# CBASS0_FW register map
Vendor: Texas Instruments
Peripheral module from a debugger description file (folder am62A).
Registers are 32-bit, read-write, reset 0x0 unless marked. A register's access mark holds for its fields unless they carry their own. Offsets are as the file gives them; lines under a group give offsets from that group; [hi:lo] are bit positions; {n}, {i} and the like mark numbered series; 'fields as' and 'values as' point back to an identical list; <NAME> marks a mode.

## CBASS0_FW (part 1 of 2)
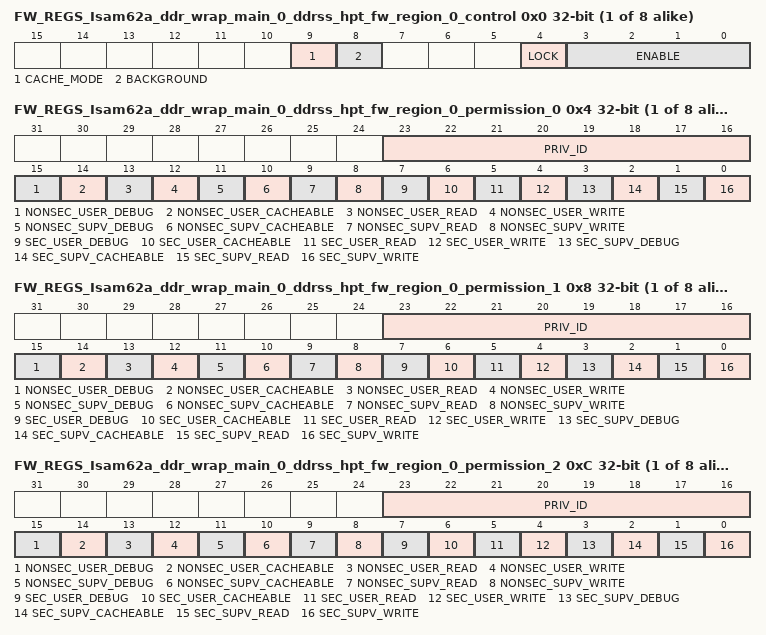
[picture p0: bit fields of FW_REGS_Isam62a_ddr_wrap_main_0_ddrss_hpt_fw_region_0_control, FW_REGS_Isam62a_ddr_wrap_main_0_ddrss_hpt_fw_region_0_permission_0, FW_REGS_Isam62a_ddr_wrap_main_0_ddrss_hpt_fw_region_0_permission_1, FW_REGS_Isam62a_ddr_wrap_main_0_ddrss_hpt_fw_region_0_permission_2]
{0x0+0x20*i} FW_REGS_Isam62a_ddr_wrap_main_0_ddrss_hpt_fw_region_{i}_control access not given (i=0..7) — The FW Region {i} Control Register defines the control fields for the slave Isam62a_ddr_wrap_main_0.ddrss_hpt region {i} firewall.
  [9] CACHE_MODE rw — Cache mode for region. Set to 1 to check cache permissions. Set to 0 to ignore cache permissions.
  [8] BACKGROUND rw — Background enable for region. There can be 1 backgroun region per FW and foreground regions can have overlapping addresses only with the background region.
  [4] LOCK — Lock region. Once set region values cannot be modified. (access R/W1TS)
  [3:0] ENABLE rw — Enable region. A value of 0xA enables, others disable.
{0x4+0x20*i} FW_REGS_Isam62a_ddr_wrap_main_0_ddrss_hpt_fw_region_{i}_permission_0 (i=0..7) — The FW Region {i} Permission 0 Register defines the permissions for the slave Isam62a_ddr_wrap_main_0.ddrss_hpt region {i} firewall.
  [23:16] PRIV_ID — Allowed privid.
  [15] NONSEC_USER_DEBUG — Non-secure user debug allowed.
  [14] NONSEC_USER_CACHEABLE — Non-secure user cacheable allowed.
  [13] NONSEC_USER_READ — Non-secure user read allowed.
  [12] NONSEC_USER_WRITE — Non-secure user write allowed.
  [11] NONSEC_SUPV_DEBUG — Non-secure supervisor debug allowed.
  [10] NONSEC_SUPV_CACHEABLE — Non-secure supervisor cacheable allowed.
  [9] NONSEC_SUPV_READ — Non-secure supervisor read allowed.
  [8] NONSEC_SUPV_WRITE — Non-secure supervisor write allowed.
  [7] SEC_USER_DEBUG — Secure user debug allowed.
  [6] SEC_USER_CACHEABLE — Secure user cacheable allowed.
  [5] SEC_USER_READ — Secure user read allowed.
  [4] SEC_USER_WRITE — Secure user write allowed.
  [3] SEC_SUPV_DEBUG — Secure supervisor debug allowed.
  [2] SEC_SUPV_CACHEABLE — Secure supervisor cacheable allowed.
  [1] SEC_SUPV_READ — Secure supervisor read allowed.
  [0] SEC_SUPV_WRITE — Secure supervisor write allowed.
{0x8+0x20*i} FW_REGS_Isam62a_ddr_wrap_main_0_ddrss_hpt_fw_region_{i}_permission_1 (i=0..7) — The FW Region {i} Permission 1 Register defines the permissions for the slave Isam62a_ddr_wrap_main_0.ddrss_hpt region {i} firewall.
  fields as FW_REGS_Isam62a_ddr_wrap_main_0_ddrss_hpt_fw_region_0_permission_0
{0xC+0x20*i} FW_REGS_Isam62a_ddr_wrap_main_0_ddrss_hpt_fw_region_{i}_permission_2 (i=0..7) — The FW Region {i} Permission 2 Register defines the permissions for the slave Isam62a_ddr_wrap_main_0.ddrss_hpt region {i} firewall.
  fields as FW_REGS_Isam62a_ddr_wrap_main_0_ddrss_hpt_fw_region_0_permission_0
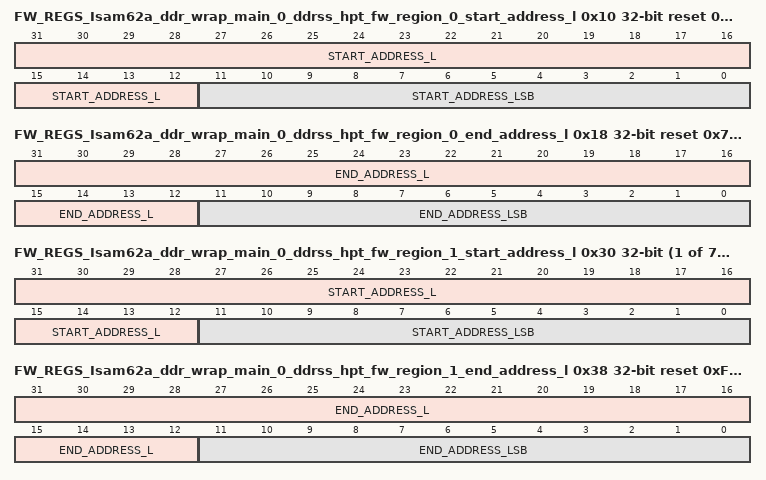
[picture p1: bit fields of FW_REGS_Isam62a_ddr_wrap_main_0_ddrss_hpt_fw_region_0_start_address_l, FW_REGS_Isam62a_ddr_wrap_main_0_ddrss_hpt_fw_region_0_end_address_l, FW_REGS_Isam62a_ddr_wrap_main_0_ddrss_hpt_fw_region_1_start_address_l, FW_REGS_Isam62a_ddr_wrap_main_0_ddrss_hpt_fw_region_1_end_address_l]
0x10 FW_REGS_Isam62a_ddr_wrap_main_0_ddrss_hpt_fw_region_0_start_address_l access per field reset 0x80000000 — The FW Region 0 Start Address Low Register defines the start address bits 31 to 0 for the slave Isam62a_ddr_wrap_main_0.ddrss_hpt region 0 firewall.
  [31:12] START_ADDRESS_L rw — Start address bits 31 to 12. Lowest 12 bits are forced to 0 as address must be 4KB aligned.
  [11:0] START_ADDRESS_LSB ro — Start address bits 11 to 0 are forced to 0 as address must be 4KB aligned.
{0x14+0x20*i} FW_REGS_Isam62a_ddr_wrap_main_0_ddrss_hpt_fw_region_{i}_start_address_h (i=0..7) — The FW Region {i} Start Address High Register defines the start address bits 47 to 32 for the slave Isam62a_ddr_wrap_main_0.ddrss_hpt region {i} firewall.
  [15:0] START_ADDRESS_H — Start address bits 47 to 32.
0x18 FW_REGS_Isam62a_ddr_wrap_main_0_ddrss_hpt_fw_region_0_end_address_l access per field reset 0x7FFFFFFF — The FW Region 0 End Address Low Register defines the end address bits 31 to 0 to include for the slave Isam62a_ddr_wrap_main_0.ddrss_hpt region 0 firewall.
  [31:12] END_ADDRESS_L rw — End address bits 31 to 12 to include in the match. Lowest 12 bits are forced to 1s as address must be 4KB aligned.
  [11:0] END_ADDRESS_LSB ro — End address bits 11 to 0 are forced to 1s as address must be 4KB aligned minus 1.
0x1C FW_REGS_Isam62a_ddr_wrap_main_0_ddrss_hpt_fw_region_0_end_address_h reset 0x8 — The FW Region 0 End Address High Register defines the end address bits 47 to 32 to include for the slave Isam62a_ddr_wrap_main_0.ddrss_hpt region 0 firewall.
  [15:0] END_ADDRESS_H — End address bits 47 to 32 to include in the match.
{0x10+0x20*i} FW_REGS_Isam62a_ddr_wrap_main_0_ddrss_hpt_fw_region_{i}_start_address_l access per field (i=1..7) — The FW Region {i} Start Address Low Register defines the start address bits 31 to 0 for the slave Isam62a_ddr_wrap_main_0.ddrss_hpt region {i} firewall.
  fields as FW_REGS_Isam62a_ddr_wrap_main_0_ddrss_hpt_fw_region_0_start_address_l
{0x18+0x20*i} FW_REGS_Isam62a_ddr_wrap_main_0_ddrss_hpt_fw_region_{i}_end_address_l access per field reset 0xFFF (i=1..7) — The FW Region {i} End Address Low Register defines the end address bits 31 to 0 to include for the slave Isam62a_ddr_wrap_main_0.ddrss_hpt region {i} firewall.
  fields as FW_REGS_Isam62a_ddr_wrap_main_0_ddrss_hpt_fw_region_0_end_address_l
{0x1C+0x20*i} FW_REGS_Isam62a_ddr_wrap_main_0_ddrss_hpt_fw_region_{i}_end_address_h (i=1..7) — The FW Region {i} End Address High Register defines the end address bits 47 to 32 to include for the slave Isam62a_ddr_wrap_main_0.ddrss_hpt region {i} firewall.
  fields as FW_REGS_Isam62a_ddr_wrap_main_0_ddrss_hpt_fw_region_0_end_address_h
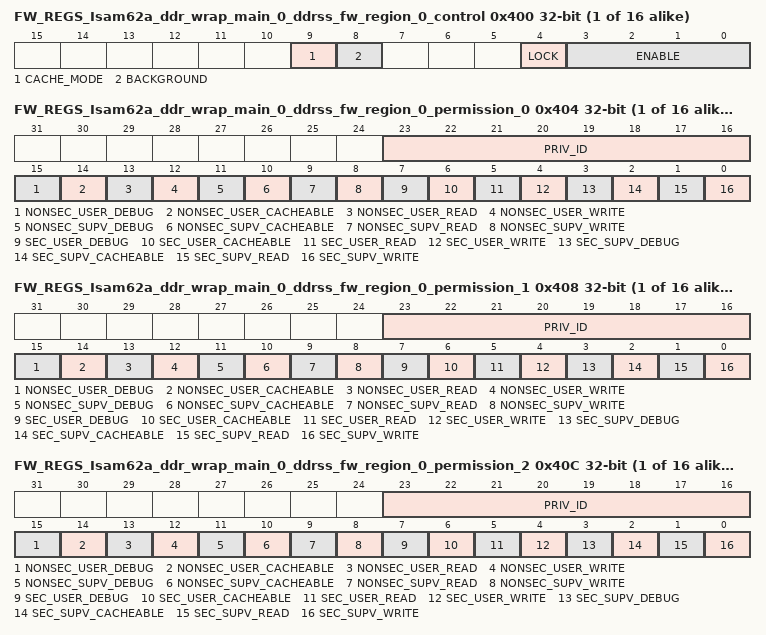
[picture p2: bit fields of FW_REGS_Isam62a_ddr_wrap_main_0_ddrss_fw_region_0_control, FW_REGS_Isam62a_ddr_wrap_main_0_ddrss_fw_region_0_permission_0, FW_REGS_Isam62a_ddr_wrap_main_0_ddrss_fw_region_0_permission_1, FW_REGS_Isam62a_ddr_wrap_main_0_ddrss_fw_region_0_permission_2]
{0x400+0x20*i} FW_REGS_Isam62a_ddr_wrap_main_0_ddrss_fw_region_{i}_control access not given (i=0..15) — The FW Region {i} Control Register defines the control fields for the slave Isam62a_ddr_wrap_main_0.ddrss region {i} firewall.
  fields as FW_REGS_Isam62a_ddr_wrap_main_0_ddrss_hpt_fw_region_0_control
{0x404+0x20*i} FW_REGS_Isam62a_ddr_wrap_main_0_ddrss_fw_region_{i}_permission_0 (i=0..15) — The FW Region {i} Permission 0 Register defines the permissions for the slave Isam62a_ddr_wrap_main_0.ddrss region {i} firewall.
  fields as FW_REGS_Isam62a_ddr_wrap_main_0_ddrss_hpt_fw_region_0_permission_0
{0x408+0x20*i} FW_REGS_Isam62a_ddr_wrap_main_0_ddrss_fw_region_{i}_permission_1 (i=0..15) — The FW Region {i} Permission 1 Register defines the permissions for the slave Isam62a_ddr_wrap_main_0.ddrss region {i} firewall.
  fields as FW_REGS_Isam62a_ddr_wrap_main_0_ddrss_hpt_fw_region_0_permission_0
{0x40C+0x20*i} FW_REGS_Isam62a_ddr_wrap_main_0_ddrss_fw_region_{i}_permission_2 (i=0..15) — The FW Region {i} Permission 2 Register defines the permissions for the slave Isam62a_ddr_wrap_main_0.ddrss region {i} firewall.
  fields as FW_REGS_Isam62a_ddr_wrap_main_0_ddrss_hpt_fw_region_0_permission_0
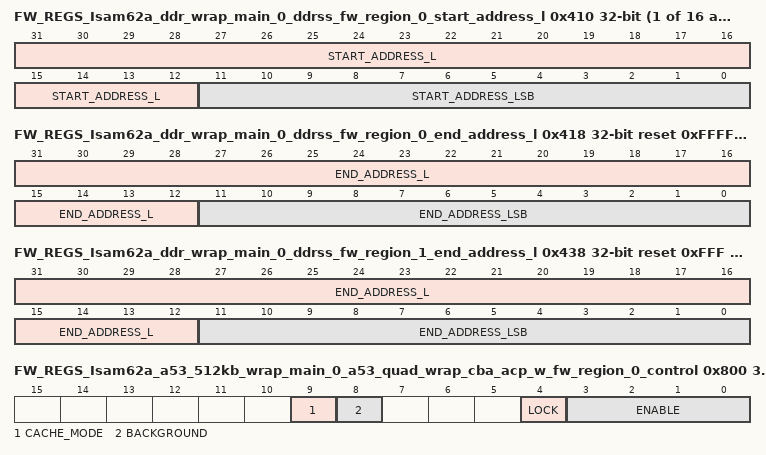
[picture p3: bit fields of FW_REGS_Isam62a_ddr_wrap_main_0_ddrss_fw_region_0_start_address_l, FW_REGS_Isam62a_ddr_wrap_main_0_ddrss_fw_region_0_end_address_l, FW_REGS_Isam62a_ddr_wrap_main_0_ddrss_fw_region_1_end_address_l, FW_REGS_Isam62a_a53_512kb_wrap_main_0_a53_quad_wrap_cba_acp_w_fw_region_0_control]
{0x410+0x20*i} FW_REGS_Isam62a_ddr_wrap_main_0_ddrss_fw_region_{i}_start_address_l access per field (i=0..15) — The FW Region {i} Start Address Low Register defines the start address bits 31 to 0 for the slave Isam62a_ddr_wrap_main_0.ddrss region {i} firewall.
  fields as FW_REGS_Isam62a_ddr_wrap_main_0_ddrss_hpt_fw_region_0_start_address_l
0x414 FW_REGS_Isam62a_ddr_wrap_main_0_ddrss_fw_region_0_start_address_h reset 0x9 — The FW Region 0 Start Address High Register defines the start address bits 47 to 32 for the slave Isam62a_ddr_wrap_main_0.ddrss region 0 firewall.
  [15:0] START_ADDRESS_H — Start address bits 47 to 32.
0x418 FW_REGS_Isam62a_ddr_wrap_main_0_ddrss_fw_region_0_end_address_l access per field reset 0xFFFFFFFF — The FW Region 0 End Address Low Register defines the end address bits 31 to 0 to include for the slave Isam62a_ddr_wrap_main_0.ddrss region 0 firewall.
  fields as FW_REGS_Isam62a_ddr_wrap_main_0_ddrss_hpt_fw_region_0_end_address_l
0x41C FW_REGS_Isam62a_ddr_wrap_main_0_ddrss_fw_region_0_end_address_h reset 0x10 — The FW Region 0 End Address High Register defines the end address bits 47 to 32 to include for the slave Isam62a_ddr_wrap_main_0.ddrss region 0 firewall.
  fields as FW_REGS_Isam62a_ddr_wrap_main_0_ddrss_hpt_fw_region_0_end_address_h
{0x414+0x20*i} FW_REGS_Isam62a_ddr_wrap_main_0_ddrss_fw_region_{i}_start_address_h (i=1..15) — The FW Region {i} Start Address High Register defines the start address bits 47 to 32 for the slave Isam62a_ddr_wrap_main_0.ddrss region {i} firewall.
  [15:0] START_ADDRESS_H — Start address bits 47 to 32.
{0x418+0x20*i} FW_REGS_Isam62a_ddr_wrap_main_0_ddrss_fw_region_{i}_end_address_l access per field reset 0xFFF (i=1..15) — The FW Region {i} End Address Low Register defines the end address bits 31 to 0 to include for the slave Isam62a_ddr_wrap_main_0.ddrss region {i} firewall.
  fields as FW_REGS_Isam62a_ddr_wrap_main_0_ddrss_hpt_fw_region_0_end_address_l
{0x41C+0x20*i} FW_REGS_Isam62a_ddr_wrap_main_0_ddrss_fw_region_{i}_end_address_h (i=1..15) — The FW Region {i} End Address High Register defines the end address bits 47 to 32 to include for the slave Isam62a_ddr_wrap_main_0.ddrss region {i} firewall.
  fields as FW_REGS_Isam62a_ddr_wrap_main_0_ddrss_hpt_fw_region_0_end_address_h
{0x800+0x20*i} FW_REGS_Isam62a_a53_512kb_wrap_main_0_a53_quad_wrap_cba_acp_w_fw_region_{i}_control access not given (i=0..7) — The FW Region {i} Control Register defines the control fields for the slave Isam62a_a53_512kb_wrap_main_0.a53_quad_wrap_cba_acp_w region {i} firewall.
  fields as FW_REGS_Isam62a_ddr_wrap_main_0_ddrss_hpt_fw_region_0_control
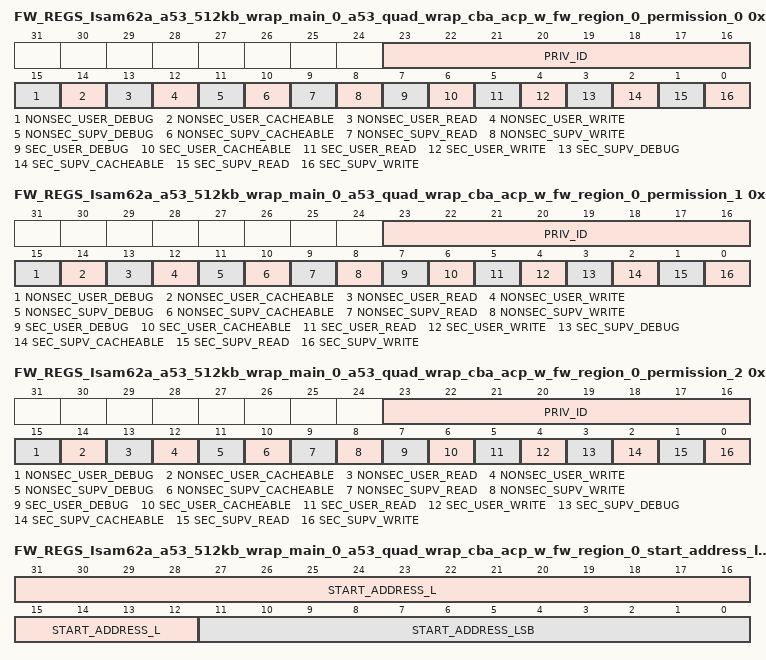
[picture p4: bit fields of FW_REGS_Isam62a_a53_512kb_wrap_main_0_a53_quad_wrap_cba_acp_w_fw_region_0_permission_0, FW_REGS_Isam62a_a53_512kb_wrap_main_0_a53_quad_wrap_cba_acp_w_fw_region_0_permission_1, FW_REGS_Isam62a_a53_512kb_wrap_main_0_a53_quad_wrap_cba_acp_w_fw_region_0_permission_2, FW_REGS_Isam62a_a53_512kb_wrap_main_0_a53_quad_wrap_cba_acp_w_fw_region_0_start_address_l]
{0x804+0x20*i} FW_REGS_Isam62a_a53_512kb_wrap_main_0_a53_quad_wrap_cba_acp_w_fw_region_{i}_permission_0 (i=0..7) — The FW Region {i} Permission 0 Register defines the permissions for the slave Isam62a_a53_512kb_wrap_main_0.a53_quad_wrap_cba_acp_w region {i} firewall.
  fields as FW_REGS_Isam62a_ddr_wrap_main_0_ddrss_hpt_fw_region_0_permission_0
{0x808+0x20*i} FW_REGS_Isam62a_a53_512kb_wrap_main_0_a53_quad_wrap_cba_acp_w_fw_region_{i}_permission_1 (i=0..7) — The FW Region {i} Permission 1 Register defines the permissions for the slave Isam62a_a53_512kb_wrap_main_0.a53_quad_wrap_cba_acp_w region {i} firewall.
  fields as FW_REGS_Isam62a_ddr_wrap_main_0_ddrss_hpt_fw_region_0_permission_0
{0x80C+0x20*i} FW_REGS_Isam62a_a53_512kb_wrap_main_0_a53_quad_wrap_cba_acp_w_fw_region_{i}_permission_2 (i=0..7) — The FW Region {i} Permission 2 Register defines the permissions for the slave Isam62a_a53_512kb_wrap_main_0.a53_quad_wrap_cba_acp_w region {i} firewall.
  fields as FW_REGS_Isam62a_ddr_wrap_main_0_ddrss_hpt_fw_region_0_permission_0
{0x810+0x20*i} FW_REGS_Isam62a_a53_512kb_wrap_main_0_a53_quad_wrap_cba_acp_w_fw_region_{i}_start_address_l access per field (i=0..7) — The FW Region {i} Start Address Low Register defines the start address bits 31 to 0 for the slave Isam62a_a53_512kb_wrap_main_0.a53_quad_wrap_cba_acp_w region {i} firewall.
  fields as FW_REGS_Isam62a_ddr_wrap_main_0_ddrss_hpt_fw_region_0_start_address_l
{0x814+0x20*i} FW_REGS_Isam62a_a53_512kb_wrap_main_0_a53_quad_wrap_cba_acp_w_fw_region_{i}_start_address_h (i=0..7) — The FW Region {i} Start Address High Register defines the start address bits 47 to 32 for the slave Isam62a_a53_512kb_wrap_main_0.a53_quad_wrap_cba_acp_w region {i} firewall.
  [15:0] START_ADDRESS_H — Start address bits 47 to 32.
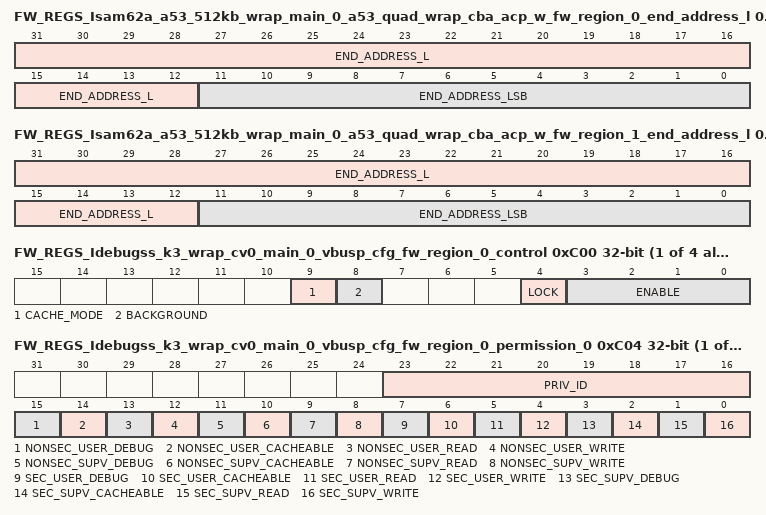
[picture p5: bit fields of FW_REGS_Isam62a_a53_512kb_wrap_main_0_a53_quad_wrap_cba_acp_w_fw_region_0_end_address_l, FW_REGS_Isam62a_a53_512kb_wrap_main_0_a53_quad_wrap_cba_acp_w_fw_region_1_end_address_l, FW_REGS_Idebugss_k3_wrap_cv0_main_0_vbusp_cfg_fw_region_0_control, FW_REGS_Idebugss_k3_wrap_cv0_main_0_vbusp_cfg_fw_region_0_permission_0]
0x818 FW_REGS_Isam62a_a53_512kb_wrap_main_0_a53_quad_wrap_cba_acp_w_fw_region_0_end_address_l access per field reset 0xFFFFFFFF — The FW Region 0 End Address Low Register defines the end address bits 31 to 0 to include for the slave Isam62a_a53_512kb_wrap_main_0.a53_quad_wrap_cba_acp_w region 0 firewall.
  fields as FW_REGS_Isam62a_ddr_wrap_main_0_ddrss_hpt_fw_region_0_end_address_l
0x81C FW_REGS_Isam62a_a53_512kb_wrap_main_0_a53_quad_wrap_cba_acp_w_fw_region_0_end_address_h reset 0xF — The FW Region 0 End Address High Register defines the end address bits 47 to 32 to include for the slave Isam62a_a53_512kb_wrap_main_0.a53_quad_wrap_cba_acp_w region 0 firewall.
  fields as FW_REGS_Isam62a_ddr_wrap_main_0_ddrss_hpt_fw_region_0_end_address_h
{0x818+0x20*i} FW_REGS_Isam62a_a53_512kb_wrap_main_0_a53_quad_wrap_cba_acp_w_fw_region_{i}_end_address_l access per field reset 0xFFF (i=1..7) — The FW Region {i} End Address Low Register defines the end address bits 31 to 0 to include for the slave Isam62a_a53_512kb_wrap_main_0.a53_quad_wrap_cba_acp_w region {i} firewall.
  fields as FW_REGS_Isam62a_ddr_wrap_main_0_ddrss_hpt_fw_region_0_end_address_l
{0x81C+0x20*i} FW_REGS_Isam62a_a53_512kb_wrap_main_0_a53_quad_wrap_cba_acp_w_fw_region_{i}_end_address_h (i=1..7) — The FW Region {i} End Address High Register defines the end address bits 47 to 32 to include for the slave Isam62a_a53_512kb_wrap_main_0.a53_quad_wrap_cba_acp_w region {i} firewall.
  fields as FW_REGS_Isam62a_ddr_wrap_main_0_ddrss_hpt_fw_region_0_end_address_h
{0xC00+0x20*i} FW_REGS_Idebugss_k3_wrap_cv0_main_0_vbusp_cfg_fw_region_{i}_control access not given (i=0..3) — The FW Region {i} Control Register defines the control fields for the slave Idebugss_k3_wrap_cv0_main_0.vbusp_cfg region {i} firewall.
  fields as FW_REGS_Isam62a_ddr_wrap_main_0_ddrss_hpt_fw_region_0_control
{0xC04+0x20*i} FW_REGS_Idebugss_k3_wrap_cv0_main_0_vbusp_cfg_fw_region_{i}_permission_0 (i=0..3) — The FW Region {i} Permission 0 Register defines the permissions for the slave Idebugss_k3_wrap_cv0_main_0.vbusp_cfg region {i} firewall.
  fields as FW_REGS_Isam62a_ddr_wrap_main_0_ddrss_hpt_fw_region_0_permission_0
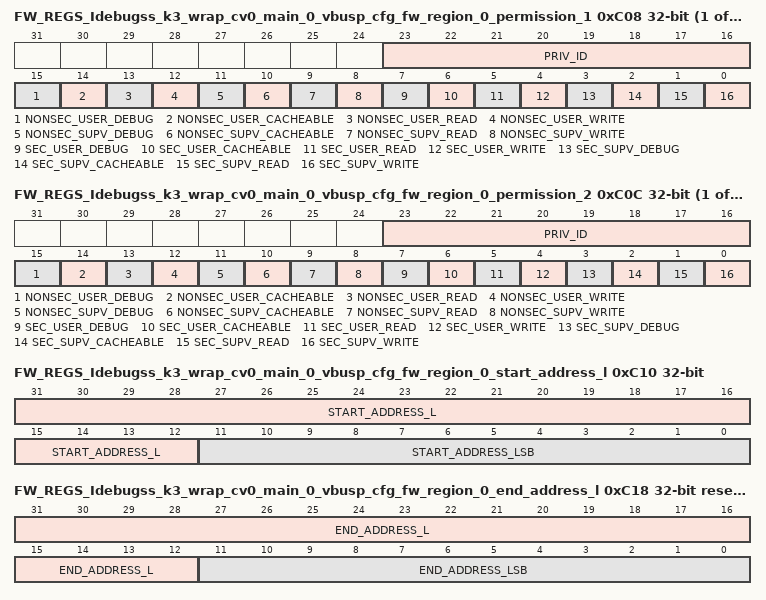
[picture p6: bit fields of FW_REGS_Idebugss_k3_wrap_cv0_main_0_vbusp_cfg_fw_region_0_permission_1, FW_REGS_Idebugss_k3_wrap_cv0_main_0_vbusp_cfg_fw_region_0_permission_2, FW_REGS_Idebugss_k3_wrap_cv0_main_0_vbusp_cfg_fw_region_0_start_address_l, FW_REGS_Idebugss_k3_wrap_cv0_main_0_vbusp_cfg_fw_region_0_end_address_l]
{0xC08+0x20*i} FW_REGS_Idebugss_k3_wrap_cv0_main_0_vbusp_cfg_fw_region_{i}_permission_1 (i=0..3) — The FW Region {i} Permission 1 Register defines the permissions for the slave Idebugss_k3_wrap_cv0_main_0.vbusp_cfg region {i} firewall.
  fields as FW_REGS_Isam62a_ddr_wrap_main_0_ddrss_hpt_fw_region_0_permission_0
{0xC0C+0x20*i} FW_REGS_Idebugss_k3_wrap_cv0_main_0_vbusp_cfg_fw_region_{i}_permission_2 (i=0..3) — The FW Region {i} Permission 2 Register defines the permissions for the slave Idebugss_k3_wrap_cv0_main_0.vbusp_cfg region {i} firewall.
  fields as FW_REGS_Isam62a_ddr_wrap_main_0_ddrss_hpt_fw_region_0_permission_0
0xC10 FW_REGS_Idebugss_k3_wrap_cv0_main_0_vbusp_cfg_fw_region_0_start_address_l access per field — The FW Region 0 Start Address Low Register defines the start address bits 31 to 0 for the slave Idebugss_k3_wrap_cv0_main_0.vbusp_cfg region 0 firewall.
  fields as FW_REGS_Isam62a_ddr_wrap_main_0_ddrss_hpt_fw_region_0_start_address_l
{0xC14+0x20*i} FW_REGS_Idebugss_k3_wrap_cv0_main_0_vbusp_cfg_fw_region_{i}_start_address_h reset 0x7 (i=0..3) — The FW Region {i} Start Address High Register defines the start address bits 47 to 32 for the slave Idebugss_k3_wrap_cv0_main_0.vbusp_cfg region {i} firewall.
  [15:0] START_ADDRESS_H — Start address bits 47 to 32.
0xC18 FW_REGS_Idebugss_k3_wrap_cv0_main_0_vbusp_cfg_fw_region_0_end_address_l access per field reset 0xFFF — The FW Region 0 End Address Low Register defines the end address bits 31 to 0 to include for the slave Idebugss_k3_wrap_cv0_main_0.vbusp_cfg region 0 firewall.
  fields as FW_REGS_Isam62a_ddr_wrap_main_0_ddrss_hpt_fw_region_0_end_address_l
{0xC1C+0x20*i} FW_REGS_Idebugss_k3_wrap_cv0_main_0_vbusp_cfg_fw_region_{i}_end_address_h reset 0x7 (i=0..3) — The FW Region {i} End Address High Register defines the end address bits 47 to 32 to include for the slave Idebugss_k3_wrap_cv0_main_0.vbusp_cfg region {i} firewall.
  fields as FW_REGS_Isam62a_ddr_wrap_main_0_ddrss_hpt_fw_region_0_end_address_h
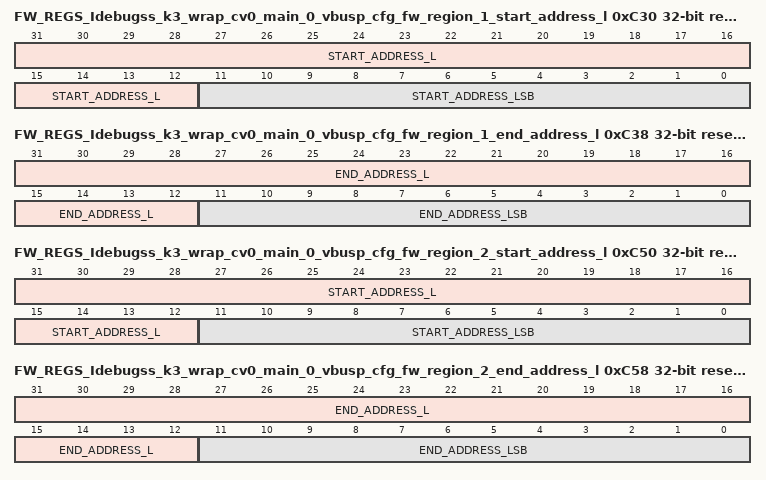
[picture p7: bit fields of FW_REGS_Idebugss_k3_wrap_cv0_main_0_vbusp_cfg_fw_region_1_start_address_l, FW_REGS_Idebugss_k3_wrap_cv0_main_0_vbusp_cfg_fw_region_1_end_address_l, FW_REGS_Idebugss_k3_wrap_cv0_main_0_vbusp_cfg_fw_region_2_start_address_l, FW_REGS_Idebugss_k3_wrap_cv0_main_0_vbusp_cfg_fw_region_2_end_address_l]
0xC30 FW_REGS_Idebugss_k3_wrap_cv0_main_0_vbusp_cfg_fw_region_1_start_address_l access per field reset 0x1000 — The FW Region 1 Start Address Low Register defines the start address bits 31 to 0 for the slave Idebugss_k3_wrap_cv0_main_0.vbusp_cfg region 1 firewall.
  fields as FW_REGS_Isam62a_ddr_wrap_main_0_ddrss_hpt_fw_region_0_start_address_l
0xC38 FW_REGS_Idebugss_k3_wrap_cv0_main_0_vbusp_cfg_fw_region_1_end_address_l access per field reset 0x1FFF — The FW Region 1 End Address Low Register defines the end address bits 31 to 0 to include for the slave Idebugss_k3_wrap_cv0_main_0.vbusp_cfg region 1 firewall.
  fields as FW_REGS_Isam62a_ddr_wrap_main_0_ddrss_hpt_fw_region_0_end_address_l
0xC50 FW_REGS_Idebugss_k3_wrap_cv0_main_0_vbusp_cfg_fw_region_2_start_address_l access per field reset 0x2000 — The FW Region 2 Start Address Low Register defines the start address bits 31 to 0 for the slave Idebugss_k3_wrap_cv0_main_0.vbusp_cfg region 2 firewall.
  fields as FW_REGS_Isam62a_ddr_wrap_main_0_ddrss_hpt_fw_region_0_start_address_l
0xC58 FW_REGS_Idebugss_k3_wrap_cv0_main_0_vbusp_cfg_fw_region_2_end_address_l access per field reset 0x2FFF — The FW Region 2 End Address Low Register defines the end address bits 31 to 0 to include for the slave Idebugss_k3_wrap_cv0_main_0.vbusp_cfg region 2 firewall.
  fields as FW_REGS_Isam62a_ddr_wrap_main_0_ddrss_hpt_fw_region_0_end_address_l
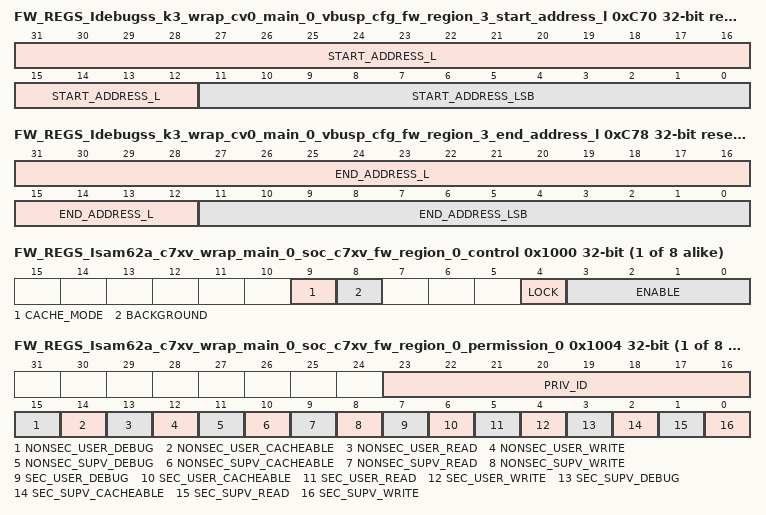
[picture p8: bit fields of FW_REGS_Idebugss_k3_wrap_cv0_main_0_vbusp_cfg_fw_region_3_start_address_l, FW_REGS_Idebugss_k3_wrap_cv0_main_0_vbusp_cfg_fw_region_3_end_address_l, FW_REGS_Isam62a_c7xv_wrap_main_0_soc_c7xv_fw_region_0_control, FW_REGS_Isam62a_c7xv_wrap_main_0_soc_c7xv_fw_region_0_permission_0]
0xC70 FW_REGS_Idebugss_k3_wrap_cv0_main_0_vbusp_cfg_fw_region_3_start_address_l access per field reset 0x2000 — The FW Region 3 Start Address Low Register defines the start address bits 31 to 0 for the slave Idebugss_k3_wrap_cv0_main_0.vbusp_cfg region 3 firewall.
  fields as FW_REGS_Isam62a_ddr_wrap_main_0_ddrss_hpt_fw_region_0_start_address_l
0xC78 FW_REGS_Idebugss_k3_wrap_cv0_main_0_vbusp_cfg_fw_region_3_end_address_l access per field reset 0x2FFF — The FW Region 3 End Address Low Register defines the end address bits 31 to 0 to include for the slave Idebugss_k3_wrap_cv0_main_0.vbusp_cfg region 3 firewall.
  fields as FW_REGS_Isam62a_ddr_wrap_main_0_ddrss_hpt_fw_region_0_end_address_l
{0x1000+0x20*i} FW_REGS_Isam62a_c7xv_wrap_main_0_soc_c7xv_fw_region_{i}_control access not given (i=0..7) — The FW Region {i} Control Register defines the control fields for the slave Isam62a_c7xv_wrap_main_0.soc_c7xv region {i} firewall.
  fields as FW_REGS_Isam62a_ddr_wrap_main_0_ddrss_hpt_fw_region_0_control
{0x1004+0x20*i} FW_REGS_Isam62a_c7xv_wrap_main_0_soc_c7xv_fw_region_{i}_permission_0 (i=0..7) — The FW Region {i} Permission 0 Register defines the permissions for the slave Isam62a_c7xv_wrap_main_0.soc_c7xv region {i} firewall.
  fields as FW_REGS_Isam62a_ddr_wrap_main_0_ddrss_hpt_fw_region_0_permission_0
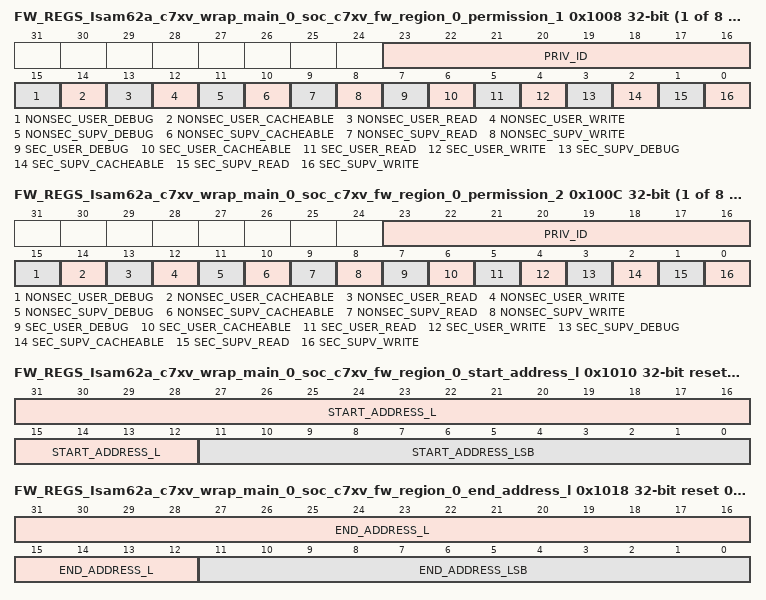
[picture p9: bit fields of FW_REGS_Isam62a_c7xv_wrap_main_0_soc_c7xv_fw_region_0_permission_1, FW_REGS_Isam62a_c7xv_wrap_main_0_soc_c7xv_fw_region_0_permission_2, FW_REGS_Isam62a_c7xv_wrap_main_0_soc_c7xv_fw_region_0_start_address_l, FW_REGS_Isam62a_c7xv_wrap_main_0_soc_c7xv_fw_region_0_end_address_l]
{0x1008+0x20*i} FW_REGS_Isam62a_c7xv_wrap_main_0_soc_c7xv_fw_region_{i}_permission_1 (i=0..7) — The FW Region {i} Permission 1 Register defines the permissions for the slave Isam62a_c7xv_wrap_main_0.soc_c7xv region {i} firewall.
  fields as FW_REGS_Isam62a_ddr_wrap_main_0_ddrss_hpt_fw_region_0_permission_0
{0x100C+0x20*i} FW_REGS_Isam62a_c7xv_wrap_main_0_soc_c7xv_fw_region_{i}_permission_2 (i=0..7) — The FW Region {i} Permission 2 Register defines the permissions for the slave Isam62a_c7xv_wrap_main_0.soc_c7xv region {i} firewall.
  fields as FW_REGS_Isam62a_ddr_wrap_main_0_ddrss_hpt_fw_region_0_permission_0
0x1010 FW_REGS_Isam62a_c7xv_wrap_main_0_soc_c7xv_fw_region_0_start_address_l access per field reset 0x7E000000 — The FW Region 0 Start Address Low Register defines the start address bits 31 to 0 for the slave Isam62a_c7xv_wrap_main_0.soc_c7xv region 0 firewall.
  fields as FW_REGS_Isam62a_ddr_wrap_main_0_ddrss_hpt_fw_region_0_start_address_l
{0x1014+0x20*i} FW_REGS_Isam62a_c7xv_wrap_main_0_soc_c7xv_fw_region_{i}_start_address_h (i=0..7) — The FW Region {i} Start Address High Register defines the start address bits 47 to 32 for the slave Isam62a_c7xv_wrap_main_0.soc_c7xv region {i} firewall.
  [15:0] START_ADDRESS_H — Start address bits 47 to 32.
0x1018 FW_REGS_Isam62a_c7xv_wrap_main_0_soc_c7xv_fw_region_0_end_address_l access per field reset 0x7E0FFFFF — The FW Region 0 End Address Low Register defines the end address bits 31 to 0 to include for the slave Isam62a_c7xv_wrap_main_0.soc_c7xv region 0 firewall.
  fields as FW_REGS_Isam62a_ddr_wrap_main_0_ddrss_hpt_fw_region_0_end_address_l
{0x101C+0x20*i} FW_REGS_Isam62a_c7xv_wrap_main_0_soc_c7xv_fw_region_{i}_end_address_h (i=0..7) — The FW Region {i} End Address High Register defines the end address bits 47 to 32 to include for the slave Isam62a_c7xv_wrap_main_0.soc_c7xv region {i} firewall.
  fields as FW_REGS_Isam62a_ddr_wrap_main_0_ddrss_hpt_fw_region_0_end_address_h
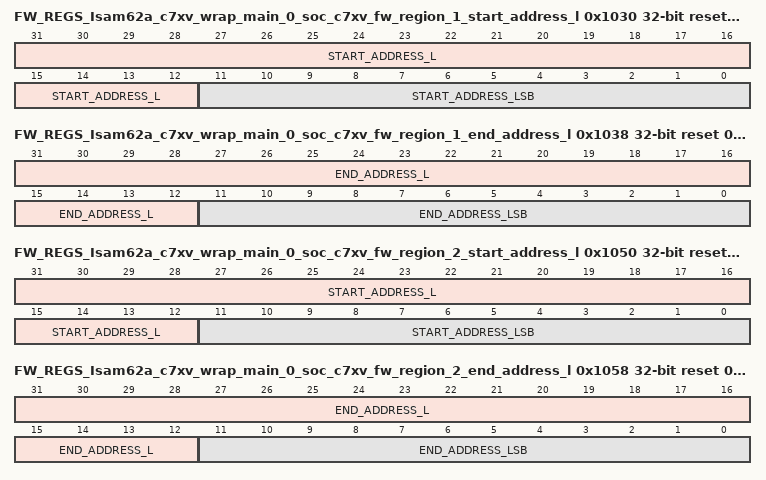
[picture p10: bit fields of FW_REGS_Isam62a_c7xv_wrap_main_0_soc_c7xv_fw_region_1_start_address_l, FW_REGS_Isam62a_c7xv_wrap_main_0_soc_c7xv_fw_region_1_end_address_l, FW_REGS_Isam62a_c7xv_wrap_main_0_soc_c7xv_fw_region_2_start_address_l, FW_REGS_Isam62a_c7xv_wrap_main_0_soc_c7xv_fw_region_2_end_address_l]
0x1030 FW_REGS_Isam62a_c7xv_wrap_main_0_soc_c7xv_fw_region_1_start_address_l access per field reset 0x7F000000 — The FW Region 1 Start Address Low Register defines the start address bits 31 to 0 for the slave Isam62a_c7xv_wrap_main_0.soc_c7xv region 1 firewall.
  fields as FW_REGS_Isam62a_ddr_wrap_main_0_ddrss_hpt_fw_region_0_start_address_l
0x1038 FW_REGS_Isam62a_c7xv_wrap_main_0_soc_c7xv_fw_region_1_end_address_l access per field reset 0x7F03FFFF — The FW Region 1 End Address Low Register defines the end address bits 31 to 0 to include for the slave Isam62a_c7xv_wrap_main_0.soc_c7xv region 1 firewall.
  fields as FW_REGS_Isam62a_ddr_wrap_main_0_ddrss_hpt_fw_region_0_end_address_l
0x1050 FW_REGS_Isam62a_c7xv_wrap_main_0_soc_c7xv_fw_region_2_start_address_l access per field reset 0x7C000000 — The FW Region 2 Start Address Low Register defines the start address bits 31 to 0 for the slave Isam62a_c7xv_wrap_main_0.soc_c7xv region 2 firewall.
  fields as FW_REGS_Isam62a_ddr_wrap_main_0_ddrss_hpt_fw_region_0_start_address_l
0x1058 FW_REGS_Isam62a_c7xv_wrap_main_0_soc_c7xv_fw_region_2_end_address_l access per field reset 0x7C01FFFF — The FW Region 2 End Address Low Register defines the end address bits 31 to 0 to include for the slave Isam62a_c7xv_wrap_main_0.soc_c7xv region 2 firewall.
  fields as FW_REGS_Isam62a_ddr_wrap_main_0_ddrss_hpt_fw_region_0_end_address_l
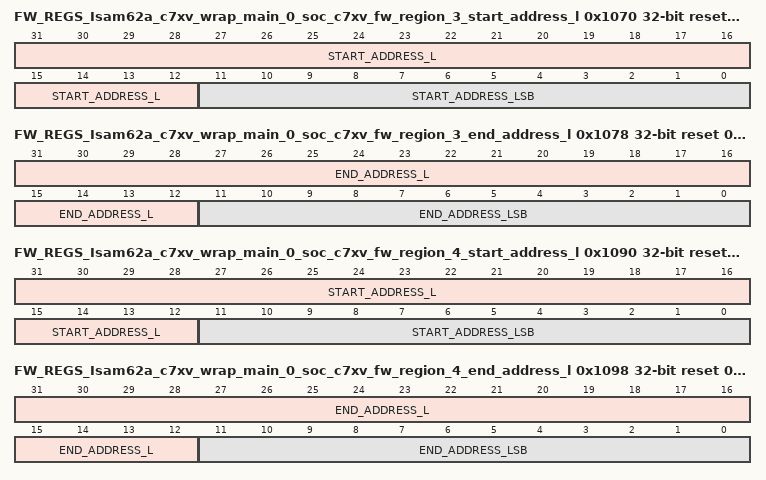
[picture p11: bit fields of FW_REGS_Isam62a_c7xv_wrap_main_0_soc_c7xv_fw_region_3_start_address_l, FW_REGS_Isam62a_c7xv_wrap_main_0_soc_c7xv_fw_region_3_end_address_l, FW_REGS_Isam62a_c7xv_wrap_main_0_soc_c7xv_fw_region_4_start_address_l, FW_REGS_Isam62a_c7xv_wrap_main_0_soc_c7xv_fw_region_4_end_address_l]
0x1070 FW_REGS_Isam62a_c7xv_wrap_main_0_soc_c7xv_fw_region_3_start_address_l access per field reset 0x7C400000 — The FW Region 3 Start Address Low Register defines the start address bits 31 to 0 for the slave Isam62a_c7xv_wrap_main_0.soc_c7xv region 3 firewall.
  fields as FW_REGS_Isam62a_ddr_wrap_main_0_ddrss_hpt_fw_region_0_start_address_l
0x1078 FW_REGS_Isam62a_c7xv_wrap_main_0_soc_c7xv_fw_region_3_end_address_l access per field reset 0x7C403FFF — The FW Region 3 End Address Low Register defines the end address bits 31 to 0 to include for the slave Isam62a_c7xv_wrap_main_0.soc_c7xv region 3 firewall.
  fields as FW_REGS_Isam62a_ddr_wrap_main_0_ddrss_hpt_fw_region_0_end_address_l
0x1090 FW_REGS_Isam62a_c7xv_wrap_main_0_soc_c7xv_fw_region_4_start_address_l access per field reset 0x7C408000 — The FW Region 4 Start Address Low Register defines the start address bits 31 to 0 for the slave Isam62a_c7xv_wrap_main_0.soc_c7xv region 4 firewall.
  fields as FW_REGS_Isam62a_ddr_wrap_main_0_ddrss_hpt_fw_region_0_start_address_l
0x1098 FW_REGS_Isam62a_c7xv_wrap_main_0_soc_c7xv_fw_region_4_end_address_l access per field reset 0x7C40FFFF — The FW Region 4 End Address Low Register defines the end address bits 31 to 0 to include for the slave Isam62a_c7xv_wrap_main_0.soc_c7xv region 4 firewall.
  fields as FW_REGS_Isam62a_ddr_wrap_main_0_ddrss_hpt_fw_region_0_end_address_l
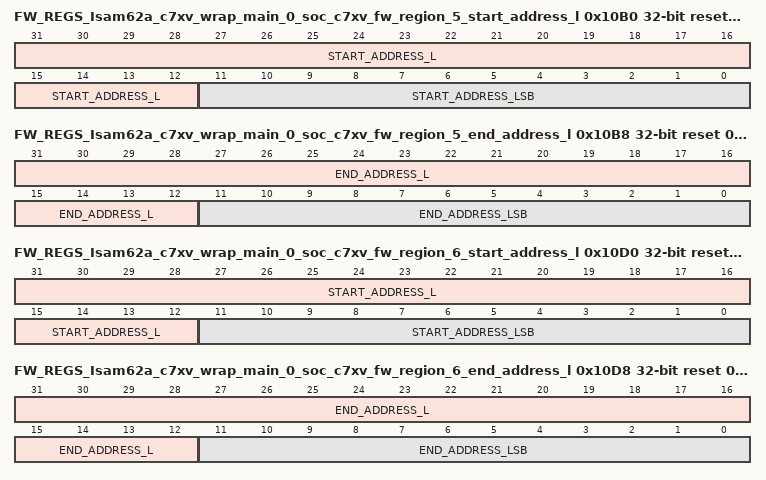
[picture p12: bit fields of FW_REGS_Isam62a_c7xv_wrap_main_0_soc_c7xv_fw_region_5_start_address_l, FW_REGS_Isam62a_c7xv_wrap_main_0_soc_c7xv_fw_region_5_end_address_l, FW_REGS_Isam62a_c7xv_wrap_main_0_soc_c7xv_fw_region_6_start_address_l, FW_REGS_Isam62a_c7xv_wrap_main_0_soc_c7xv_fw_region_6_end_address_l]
0x10B0 FW_REGS_Isam62a_c7xv_wrap_main_0_soc_c7xv_fw_region_5_start_address_l access per field reset 0x7C404000 — The FW Region 5 Start Address Low Register defines the start address bits 31 to 0 for the slave Isam62a_c7xv_wrap_main_0.soc_c7xv region 5 firewall.
  fields as FW_REGS_Isam62a_ddr_wrap_main_0_ddrss_hpt_fw_region_0_start_address_l
0x10B8 FW_REGS_Isam62a_c7xv_wrap_main_0_soc_c7xv_fw_region_5_end_address_l access per field reset 0x7C407FFF — The FW Region 5 End Address Low Register defines the end address bits 31 to 0 to include for the slave Isam62a_c7xv_wrap_main_0.soc_c7xv region 5 firewall.
  fields as FW_REGS_Isam62a_ddr_wrap_main_0_ddrss_hpt_fw_region_0_end_address_l
0x10D0 FW_REGS_Isam62a_c7xv_wrap_main_0_soc_c7xv_fw_region_6_start_address_l access per field reset 0x7C440000 — The FW Region 6 Start Address Low Register defines the start address bits 31 to 0 for the slave Isam62a_c7xv_wrap_main_0.soc_c7xv region 6 firewall.
  fields as FW_REGS_Isam62a_ddr_wrap_main_0_ddrss_hpt_fw_region_0_start_address_l
0x10D8 FW_REGS_Isam62a_c7xv_wrap_main_0_soc_c7xv_fw_region_6_end_address_l access per field reset 0x7C45FFFF — The FW Region 6 End Address Low Register defines the end address bits 31 to 0 to include for the slave Isam62a_c7xv_wrap_main_0.soc_c7xv region 6 firewall.
  fields as FW_REGS_Isam62a_ddr_wrap_main_0_ddrss_hpt_fw_region_0_end_address_l
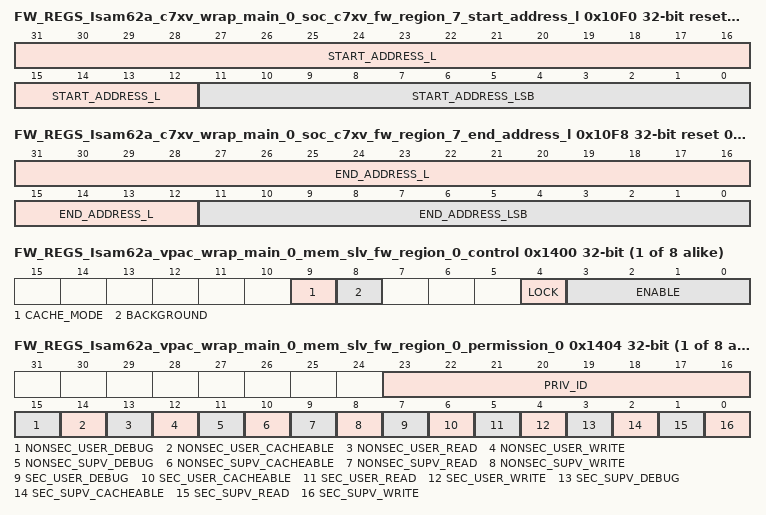
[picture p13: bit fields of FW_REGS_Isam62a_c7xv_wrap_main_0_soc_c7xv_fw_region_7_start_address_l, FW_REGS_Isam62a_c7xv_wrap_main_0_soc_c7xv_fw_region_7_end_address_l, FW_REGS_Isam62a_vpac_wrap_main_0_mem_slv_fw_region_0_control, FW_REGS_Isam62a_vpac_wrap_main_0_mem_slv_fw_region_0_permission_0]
0x10F0 FW_REGS_Isam62a_c7xv_wrap_main_0_soc_c7xv_fw_region_7_start_address_l access per field reset 0x7C460000 — The FW Region 7 Start Address Low Register defines the start address bits 31 to 0 for the slave Isam62a_c7xv_wrap_main_0.soc_c7xv region 7 firewall.
  fields as FW_REGS_Isam62a_ddr_wrap_main_0_ddrss_hpt_fw_region_0_start_address_l
0x10F8 FW_REGS_Isam62a_c7xv_wrap_main_0_soc_c7xv_fw_region_7_end_address_l access per field reset 0x7C47FFFF — The FW Region 7 End Address Low Register defines the end address bits 31 to 0 to include for the slave Isam62a_c7xv_wrap_main_0.soc_c7xv region 7 firewall.
  fields as FW_REGS_Isam62a_ddr_wrap_main_0_ddrss_hpt_fw_region_0_end_address_l
{0x1400+0x20*i} FW_REGS_Isam62a_vpac_wrap_main_0_mem_slv_fw_region_{i}_control access not given (i=0..7) — The FW Region {i} Control Register defines the control fields for the slave Isam62a_vpac_wrap_main_0.mem_slv region {i} firewall.
  fields as FW_REGS_Isam62a_ddr_wrap_main_0_ddrss_hpt_fw_region_0_control
{0x1404+0x20*i} FW_REGS_Isam62a_vpac_wrap_main_0_mem_slv_fw_region_{i}_permission_0 (i=0..7) — The FW Region {i} Permission 0 Register defines the permissions for the slave Isam62a_vpac_wrap_main_0.mem_slv region {i} firewall.
  fields as FW_REGS_Isam62a_ddr_wrap_main_0_ddrss_hpt_fw_region_0_permission_0
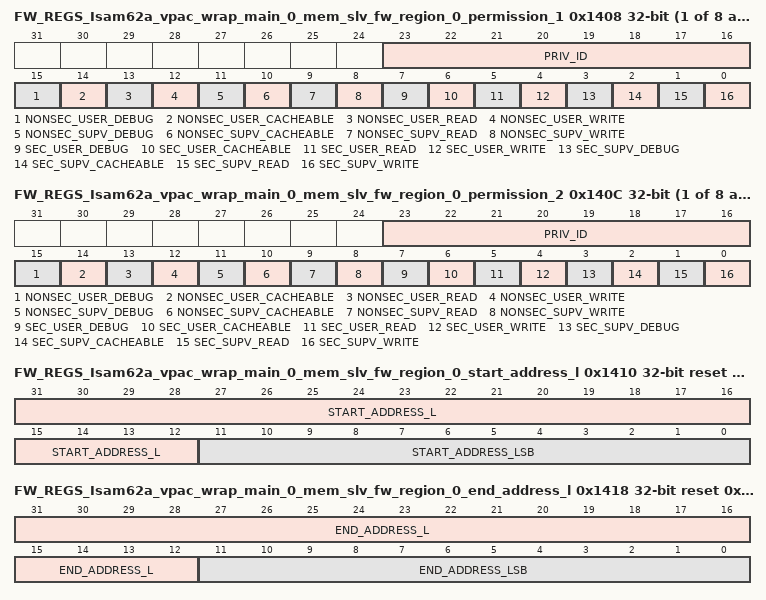
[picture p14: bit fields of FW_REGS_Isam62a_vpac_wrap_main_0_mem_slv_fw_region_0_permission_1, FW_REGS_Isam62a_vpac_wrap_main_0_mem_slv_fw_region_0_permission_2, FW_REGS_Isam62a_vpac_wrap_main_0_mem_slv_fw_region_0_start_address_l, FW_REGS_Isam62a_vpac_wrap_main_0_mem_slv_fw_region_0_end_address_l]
{0x1408+0x20*i} FW_REGS_Isam62a_vpac_wrap_main_0_mem_slv_fw_region_{i}_permission_1 (i=0..7) — The FW Region {i} Permission 1 Register defines the permissions for the slave Isam62a_vpac_wrap_main_0.mem_slv region {i} firewall.
  fields as FW_REGS_Isam62a_ddr_wrap_main_0_ddrss_hpt_fw_region_0_permission_0
{0x140C+0x20*i} FW_REGS_Isam62a_vpac_wrap_main_0_mem_slv_fw_region_{i}_permission_2 (i=0..7) — The FW Region {i} Permission 2 Register defines the permissions for the slave Isam62a_vpac_wrap_main_0.mem_slv region {i} firewall.
  fields as FW_REGS_Isam62a_ddr_wrap_main_0_ddrss_hpt_fw_region_0_permission_0
0x1410 FW_REGS_Isam62a_vpac_wrap_main_0_mem_slv_fw_region_0_start_address_l access per field reset 0x71000000 — The FW Region 0 Start Address Low Register defines the start address bits 31 to 0 for the slave Isam62a_vpac_wrap_main_0.mem_slv region 0 firewall.
  fields as FW_REGS_Isam62a_ddr_wrap_main_0_ddrss_hpt_fw_region_0_start_address_l
{0x1414+0x20*i} FW_REGS_Isam62a_vpac_wrap_main_0_mem_slv_fw_region_{i}_start_address_h (i=0..7) — The FW Region {i} Start Address High Register defines the start address bits 47 to 32 for the slave Isam62a_vpac_wrap_main_0.mem_slv region {i} firewall.
  [15:0] START_ADDRESS_H — Start address bits 47 to 32.
0x1418 FW_REGS_Isam62a_vpac_wrap_main_0_mem_slv_fw_region_0_end_address_l access per field reset 0x7107FFFF — The FW Region 0 End Address Low Register defines the end address bits 31 to 0 to include for the slave Isam62a_vpac_wrap_main_0.mem_slv region 0 firewall.
  fields as FW_REGS_Isam62a_ddr_wrap_main_0_ddrss_hpt_fw_region_0_end_address_l
{0x141C+0x20*i} FW_REGS_Isam62a_vpac_wrap_main_0_mem_slv_fw_region_{i}_end_address_h (i=0..7) — The FW Region {i} End Address High Register defines the end address bits 47 to 32 to include for the slave Isam62a_vpac_wrap_main_0.mem_slv region {i} firewall.
  fields as FW_REGS_Isam62a_ddr_wrap_main_0_ddrss_hpt_fw_region_0_end_address_h
{0x1410+0x20*i} FW_REGS_Isam62a_vpac_wrap_main_0_mem_slv_fw_region_{i}_start_address_l access per field (i=1..7) — The FW Region {i} Start Address Low Register defines the start address bits 31 to 0 for the slave Isam62a_vpac_wrap_main_0.mem_slv region {i} firewall.
  fields as FW_REGS_Isam62a_ddr_wrap_main_0_ddrss_hpt_fw_region_0_start_address_l
{0x1418+0x20*i} FW_REGS_Isam62a_vpac_wrap_main_0_mem_slv_fw_region_{i}_end_address_l access per field reset 0xFFF (i=1..7) — The FW Region {i} End Address Low Register defines the end address bits 31 to 0 to include for the slave Isam62a_vpac_wrap_main_0.mem_slv region {i} firewall.
  fields as FW_REGS_Isam62a_ddr_wrap_main_0_ddrss_hpt_fw_region_0_end_address_l
{0x1800+0x20*i} FW_REGS_Igpmc_main_0_gpmc_fw_region_{i}_control access not given (i=0..7) — The FW Region {i} Control Register defines the control fields for the slave Igpmc_main_0.gpmc region {i} firewall.
  fields as FW_REGS_Isam62a_ddr_wrap_main_0_ddrss_hpt_fw_region_0_control
